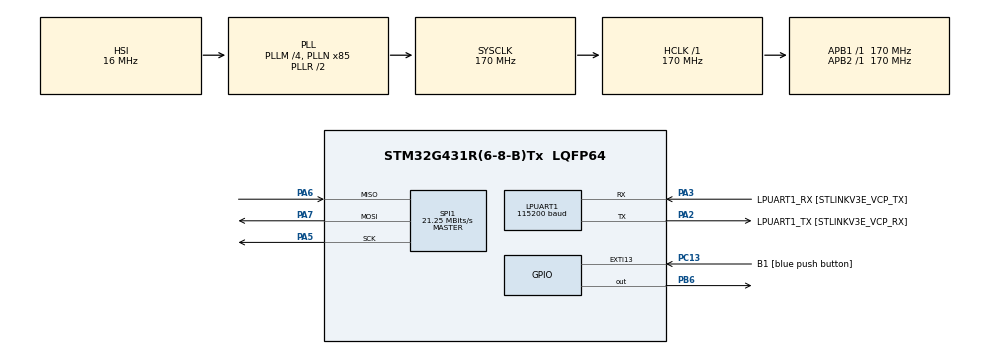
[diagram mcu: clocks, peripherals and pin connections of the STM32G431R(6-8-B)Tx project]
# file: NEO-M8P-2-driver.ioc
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LPUART1.BaudRate=115200
LPUART1.WordLength=UART_WORDLENGTH_8B
Mcu.Family=STM32G4
Mcu.Name=STM32G431R(6-8-B)Tx
Mcu.Package=LQFP64
NVIC.PriorityGroup=NVIC_PRIORITYGROUP_4
PA13.GPIO_Label=T_SWDIO
PA13.Mode=Serial_Wire
PA13.Signal=SYS_JTMS-SWDIO
PA14.GPIO_Label=T_SWCLK
PA14.Mode=Serial_Wire
PA14.Signal=SYS_JTCK-SWCLK
PA2.GPIO_Label=LPUART1_TX [STLINKV3E_VCP_RX]
PA2.Mode=Asynchronous
PA2.Signal=LPUART1_TX
PA3.GPIO_Label=LPUART1_RX [STLINKV3E_VCP_TX]
PA3.Mode=Asynchronous
PA3.Signal=LPUART1_RX
PA5.Mode=Full_Duplex_Master
PA5.Signal=SPI1_SCK
PA6.Mode=Full_Duplex_Master
PA6.Signal=SPI1_MISO
PA7.Mode=Full_Duplex_Master
PA7.Signal=SPI1_MOSI
PB3.GPIO_Label=T_SWO
PB3.Signal=SYS_JTDO-SWO
PB6.Signal=GPIO_Output
PC13.GPIO_Label=B1 [blue push button]
PC13.Signal=GPXTI13
PC14-OSC32_IN.Mode=LSE-External-Oscillator
PC14-OSC32_IN.Signal=RCC_OSC32_IN
PC15-OSC32_OUT.Mode=LSE-External-Oscillator
PC15-OSC32_OUT.Signal=RCC_OSC32_OUT
PF0-OSC_IN.Mode=HSE-External-Oscillator
PF0-OSC_IN.Signal=RCC_OSC_IN
PF1-OSC_OUT.Mode=HSE-External-Oscillator
PF1-OSC_OUT.Signal=RCC_OSC_OUT
ProjectManager.HeapSize=0x200
ProjectManager.StackSize=0x400
ProjectManager.TargetToolchain=STM32CubeIDE
RCC.ADC12Freq_Value=170000000
RCC.AHBFreq_Value=170000000
RCC.APB1Freq_Value=170000000
RCC.APB1TimFreq_Value=170000000
RCC.APB2Freq_Value=170000000
RCC.APB2TimFreq_Value=170000000
RCC.CortexFreq_Value=170000000
RCC.EXTERNAL_CLOCK_VALUE=12288000
RCC.HCLKFreq_Value=170000000
RCC.HSE_VALUE=24000000
RCC.HSI48_VALUE=48000000
RCC.HSI_VALUE=16000000
RCC.PLLM=RCC_PLLM_DIV4
RCC.PLLN=85
RCC.RTCClockSelection=RCC_RTCCLKSOURCE_LSE
RCC.SYSCLKFreq_VALUE=170000000
RCC.SYSCLKSource=RCC_SYSCLKSOURCE_PLLCLK
RCC.USBFreq_Value=170000000
RCC.VCOOutputFreq_Value=340000000
SPI1.BaudRatePrescaler=SPI_BAUDRATEPRESCALER_8
SPI1.CalculateBaudRate=21.25 MBits/s
SPI1.DataSize=SPI_DATASIZE_8BIT
SPI1.Direction=SPI_DIRECTION_2LINES
SPI1.FirstBit=SPI_FIRSTBIT_LSB
SPI1.Mode=SPI_MODE_MASTER
SPI1.VirtualType=VM_MASTER
VP_SYS_VS_DBSignals.Mode=DisableDeadBatterySignals
board=NUCLEO-G431RB

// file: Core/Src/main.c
/* USER CODE BEGIN Header */
/**
  ******************************************************************************
  * @file           : main.c
  * @brief          : Main program body
  ******************************************************************************
  * @attention
  *
  * Copyright (c) 2022 STMicroelectronics.
  * All rights reserved.
  *
  * This software is licensed under terms that can be found in the LICENSE file
  * in the root directory of this software component.
  * If no LICENSE file comes with this software, it is provided AS-IS.
  *
  ******************************************************************************
  */
/* USER CODE END Header */
#include "main.h"

/* USER CODE BEGIN Includes */
#include <stdio.h>
#include <string.h>
/* USER CODE END Includes */

UART_HandleTypeDef hlpuart1;

SPI_HandleTypeDef hspi1;

void SystemClock_Config(void);
static void MX_GPIO_Init(void);
static void MX_LPUART1_UART_Init(void);
static void MX_SPI1_Init(void);

int main(void)
{

  /* MCU Configuration--------------------------------------------------------*/

  /* Reset of all peripherals, Initializes the Flash interface and the Systick. */
  HAL_Init();

  /* Configure the system clock */
  SystemClock_Config();

  /* Initialize all configured peripherals */
  MX_GPIO_Init();
  MX_LPUART1_UART_Init();
  MX_SPI1_Init();
  /* USER CODE BEGIN 2 */
  char uart_buf[100];
  uint16_t uart_buf_len = 0;
  char spi_buf[100];
  uint16_t spi_buf_len = 80;
  /* USER CODE END 2 */

  /* Infinite loop */
  /* USER CODE BEGIN WHILE */
  while (1)
  {
	  uart_buf_len = sprintf(uart_buf, "Waiting for NMEA message\r\n");
	  HAL_UART_Transmit(&hlpuart1, (uint8_t* )uart_buf, uart_buf_len, HAL_MAX_DELAY);

	  HAL_GPIO_WritePin(GPIOB, GPIO_PIN_6, GPIO_PIN_RESET);
	  HAL_SPI_Receive(&hspi1, (uint8_t* )spi_buf, spi_buf_len, HAL_MAX_DELAY);
	  HAL_GPIO_WritePin(GPIOB, GPIO_PIN_6, GPIO_PIN_SET);

	  HAL_UART_Transmit(&hlpuart1, (uint8_t* )spi_buf, spi_buf_len, HAL_MAX_DELAY);

	  HAL_Delay(100);
    /* USER CODE END WHILE */

  }
}

void SystemClock_Config(void)
{
  RCC_OscInitTypeDef RCC_OscInitStruct = {0};
  RCC_ClkInitTypeDef RCC_ClkInitStruct = {0};

  /** Configure the main internal regulator output voltage
  */
  HAL_PWREx_ControlVoltageScaling(PWR_REGULATOR_VOLTAGE_SCALE1_BOOST);

  /** Initializes the RCC Oscillators according to the specified parameters
  * in the RCC_OscInitTypeDef structure.
  */
  RCC_OscInitStruct.OscillatorType = RCC_OSCILLATORTYPE_HSI;
  RCC_OscInitStruct.HSIState = RCC_HSI_ON;
  RCC_OscInitStruct.HSICalibrationValue = RCC_HSICALIBRATION_DEFAULT;
  RCC_OscInitStruct.PLL.PLLState = RCC_PLL_ON;
  RCC_OscInitStruct.PLL.PLLSource = RCC_PLLSOURCE_HSI;
  RCC_OscInitStruct.PLL.PLLM = RCC_PLLM_DIV4;
  RCC_OscInitStruct.PLL.PLLN = 85;
  RCC_OscInitStruct.PLL.PLLP = RCC_PLLP_DIV2;
  RCC_OscInitStruct.PLL.PLLQ = RCC_PLLQ_DIV2;
  RCC_OscInitStruct.PLL.PLLR = RCC_PLLR_DIV2;
  if (HAL_RCC_OscConfig(&RCC_OscInitStruct) != HAL_OK)
  {
    Error_Handler();
  }

  /** Initializes the CPU, AHB and APB buses clocks
  */
  RCC_ClkInitStruct.ClockType = RCC_CLOCKTYPE_HCLK|RCC_CLOCKTYPE_SYSCLK
                              |RCC_CLOCKTYPE_PCLK1|RCC_CLOCKTYPE_PCLK2;
  RCC_ClkInitStruct.SYSCLKSource = RCC_SYSCLKSOURCE_PLLCLK;
  RCC_ClkInitStruct.AHBCLKDivider = RCC_SYSCLK_DIV1;
  RCC_ClkInitStruct.APB1CLKDivider = RCC_HCLK_DIV1;
  RCC_ClkInitStruct.APB2CLKDivider = RCC_HCLK_DIV1;

  if (HAL_RCC_ClockConfig(&RCC_ClkInitStruct, FLASH_LATENCY_4) != HAL_OK)
  {
    Error_Handler();
  }
}

static void MX_LPUART1_UART_Init(void)
{

  hlpuart1.Instance = LPUART1;
  hlpuart1.Init.BaudRate = 115200;
  hlpuart1.Init.WordLength = UART_WORDLENGTH_8B;
  hlpuart1.Init.StopBits = UART_STOPBITS_1;
  hlpuart1.Init.Parity = UART_PARITY_NONE;
  hlpuart1.Init.Mode = UART_MODE_TX_RX;
  hlpuart1.Init.HwFlowCtl = UART_HWCONTROL_NONE;
  hlpuart1.Init.OneBitSampling = UART_ONE_BIT_SAMPLE_DISABLE;
  hlpuart1.Init.ClockPrescaler = UART_PRESCALER_DIV1;
  hlpuart1.AdvancedInit.AdvFeatureInit = UART_ADVFEATURE_NO_INIT;
  if (HAL_UART_Init(&hlpuart1) != HAL_OK)
  {
    Error_Handler();
  }
  if (HAL_UARTEx_SetTxFifoThreshold(&hlpuart1, UART_TXFIFO_THRESHOLD_1_8) != HAL_OK)
  {
    Error_Handler();
  }
  if (HAL_UARTEx_SetRxFifoThreshold(&hlpuart1, UART_RXFIFO_THRESHOLD_1_8) != HAL_OK)
  {
    Error_Handler();
  }
  if (HAL_UARTEx_DisableFifoMode(&hlpuart1) != HAL_OK)
  {
    Error_Handler();
  }

}

static void MX_SPI1_Init(void)
{

  /* SPI1 parameter configuration*/
  hspi1.Instance = SPI1;
  hspi1.Init.Mode = SPI_MODE_MASTER;
  hspi1.Init.Direction = SPI_DIRECTION_2LINES;
  hspi1.Init.DataSize = SPI_DATASIZE_8BIT;
  hspi1.Init.CLKPolarity = SPI_POLARITY_LOW;
  hspi1.Init.CLKPhase = SPI_PHASE_1EDGE;
  hspi1.Init.NSS = SPI_NSS_SOFT;
  hspi1.Init.BaudRatePrescaler = SPI_BAUDRATEPRESCALER_64;
  hspi1.Init.FirstBit = SPI_FIRSTBIT_MSB;
  hspi1.Init.TIMode = SPI_TIMODE_DISABLE;
  hspi1.Init.CRCCalculation = SPI_CRCCALCULATION_DISABLE;
  hspi1.Init.CRCPolynomial = 7;
  hspi1.Init.CRCLength = SPI_CRC_LENGTH_DATASIZE;
  hspi1.Init.NSSPMode = SPI_NSS_PULSE_DISABLE;
  if (HAL_SPI_Init(&hspi1) != HAL_OK)
  {
    Error_Handler();
  }

}

static void MX_GPIO_Init(void)
{
  GPIO_InitTypeDef GPIO_InitStruct = {0};

  /* GPIO Ports Clock Enable */
  __HAL_RCC_GPIOC_CLK_ENABLE();
  __HAL_RCC_GPIOF_CLK_ENABLE();
  __HAL_RCC_GPIOA_CLK_ENABLE();
  __HAL_RCC_GPIOB_CLK_ENABLE();

  /*Configure GPIO pin Output Level */
  HAL_GPIO_WritePin(GPIOB, GPIO_PIN_6, GPIO_PIN_RESET);

  /*Configure GPIO pin : B1_Pin */
  GPIO_InitStruct.Pin = B1_Pin;
  GPIO_InitStruct.Mode = GPIO_MODE_IT_RISING;
  GPIO_InitStruct.Pull = GPIO_NOPULL;
  HAL_GPIO_Init(B1_GPIO_Port, &GPIO_InitStruct);

  /*Configure GPIO pin : PB6 */
  GPIO_InitStruct.Pin = GPIO_PIN_6;
  GPIO_InitStruct.Mode = GPIO_MODE_OUTPUT_PP;
  GPIO_InitStruct.Pull = GPIO_NOPULL;
  GPIO_InitStruct.Speed = GPIO_SPEED_FREQ_LOW;
  HAL_GPIO_Init(GPIOB, &GPIO_InitStruct);

}

void Error_Handler(void)
{
  __disable_irq();
  while (1)
  {
  }
}
